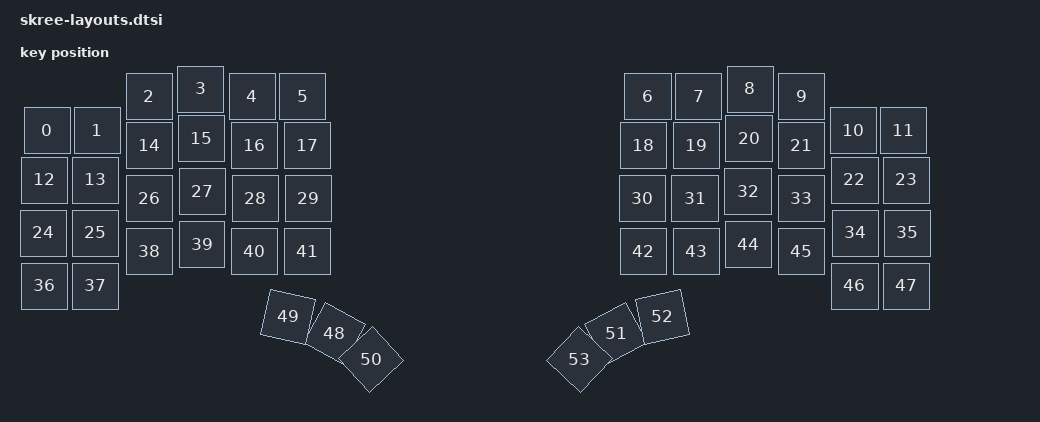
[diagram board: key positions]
#include <physical_layouts.dtsi>

/ {
    default_layout: physical_layout_0 {
        compatible = "zmk,physical-layout";
        display-name = "Default Layout";
        transform = <&default_transform>;

        keys
            = <&key_physical_attrs 100 100 8 83 0 0 0>
            , <&key_physical_attrs 100 100 108 83 0 0 0>
            , <&key_physical_attrs 100 100 212 15 0 0 0>
            , <&key_physical_attrs 100 100 315 0 0 0 0>
            , <&key_physical_attrs 100 100 418 15 0 0 0>
            , <&key_physical_attrs 100 100 519 15 0 0 0>
            , <&key_physical_attrs 100 100 1210 15 0 0 0>
            , <&key_physical_attrs 100 100 1311 15 0 0 0>
            , <&key_physical_attrs 100 100 1414 0 0 0 0>
            , <&key_physical_attrs 100 100 1517 15 0 0 0>
            , <&key_physical_attrs 100 100 1621 83 0 0 0>
            , <&key_physical_attrs 100 100 1721 83 0 0 0>
            , <&key_physical_attrs 100 100 2 182 0 0 0>
            , <&key_physical_attrs 100 100 105 182 0 0 0>
            , <&key_physical_attrs 100 100 212 113 0 0 0>
            , <&key_physical_attrs 100 100 317 99 0 0 0>
            , <&key_physical_attrs 100 100 423 113 0 0 0>
            , <&key_physical_attrs 100 100 528 113 0 0 0>
            , <&key_physical_attrs 100 100 1201 113 0 0 0>
            , <&key_physical_attrs 100 100 1306 113 0 0 0>
            , <&key_physical_attrs 100 100 1412 99 0 0 0>
            , <&key_physical_attrs 100 100 1517 113 0 0 0>
            , <&key_physical_attrs 100 100 1624 182 0 0 0>
            , <&key_physical_attrs 100 100 1727 182 0 0 0>
            , <&key_physical_attrs 100 100 0 288 0 0 0>
            , <&key_physical_attrs 100 100 104 288 0 0 0>
            , <&key_physical_attrs 100 100 212 219 0 0 0>
            , <&key_physical_attrs 100 100 319 205 0 0 0>
            , <&key_physical_attrs 100 100 425 219 0 0 0>
            , <&key_physical_attrs 100 100 531 219 0 0 0>
            , <&key_physical_attrs 100 100 1198 219 0 0 0>
            , <&key_physical_attrs 100 100 1304 219 0 0 0>
            , <&key_physical_attrs 100 100 1410 205 0 0 0>
            , <&key_physical_attrs 100 100 1517 219 0 0 0>
            , <&key_physical_attrs 100 100 1625 288 0 0 0>
            , <&key_physical_attrs 100 100 1729 288 0 0 0>
            , <&key_physical_attrs 100 100 2 394 0 0 0>
            , <&key_physical_attrs 100 100 105 394 0 0 0>
            , <&key_physical_attrs 100 100 212 325 0 0 0>
            , <&key_physical_attrs 100 100 318 311 0 0 0>
            , <&key_physical_attrs 100 100 423 325 0 0 0>
            , <&key_physical_attrs 100 100 528 325 0 0 0>
            , <&key_physical_attrs 100 100 1201 325 0 0 0>
            , <&key_physical_attrs 100 100 1306 325 0 0 0>
            , <&key_physical_attrs 100 100 1411 311 0 0 0>
            , <&key_physical_attrs 100 100 1517 325 0 0 0>
            , <&key_physical_attrs 100 100 1624 394 0 0 0>
            , <&key_physical_attrs 100 100 1727 394 0 0 0>
            , <&key_physical_attrs 100 100 583 489 2824 633 539>
            , <&key_physical_attrs 100 100 490 456 1162 540 506>
            , <&key_physical_attrs 100 100 656 541 4693 706 591>
            , <&key_physical_attrs 100 100 1146 489 (-2824) 1196 539>
            , <&key_physical_attrs 100 100 1239 456 (-1162) 1289 506>
            , <&key_physical_attrs 100 100 1073 541 (-4693) 1123 591>
            ;
    };
};
